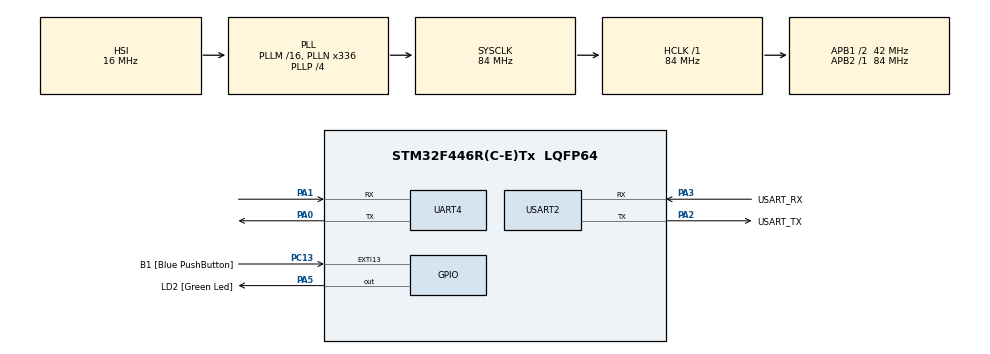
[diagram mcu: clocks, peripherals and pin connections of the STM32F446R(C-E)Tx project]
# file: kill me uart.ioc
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Mcu.Family=STM32F4
Mcu.Name=STM32F446R(C-E)Tx
Mcu.Package=LQFP64
NVIC.PriorityGroup=NVIC_PRIORITYGROUP_0
PA0-WKUP.Mode=Asynchronous
PA0-WKUP.Signal=UART4_TX
PA1.Mode=Asynchronous
PA1.Signal=UART4_RX
PA13.GPIO_Label=TMS
PA13.Mode=Serial_Wire
PA13.Signal=SYS_JTMS-SWDIO
PA14.GPIO_Label=TCK
PA14.Mode=Serial_Wire
PA14.Signal=SYS_JTCK-SWCLK
PA2.GPIO_Label=USART_TX
PA2.Mode=Asynchronous
PA2.Signal=USART2_TX
PA3.GPIO_Label=USART_RX
PA3.Mode=Asynchronous
PA3.Signal=USART2_RX
PA5.GPIO_Label=LD2 [Green Led]
PA5.Signal=GPIO_Output
PB3.GPIO_Label=SWO
PB3.Signal=SYS_JTDO-SWO
PC13.GPIO_Label=B1 [Blue PushButton]
PC13.GPIO_ModeDefaultEXTI=GPIO_MODE_IT_FALLING
PC13.Signal=GPXTI13
PC14-OSC32_IN.Mode=LSE-External-Oscillator
PC14-OSC32_IN.Signal=RCC_OSC32_IN
PC15-OSC32_OUT.Mode=LSE-External-Oscillator
PC15-OSC32_OUT.Signal=RCC_OSC32_OUT
PH0-OSC_IN.Mode=HSE-External-Oscillator
PH0-OSC_IN.Signal=RCC_OSC_IN
PH1-OSC_OUT.Mode=HSE-External-Oscillator
PH1-OSC_OUT.Signal=RCC_OSC_OUT
ProjectManager.HeapSize=0x200
ProjectManager.StackSize=0x400
ProjectManager.TargetToolchain=STM32CubeIDE
RCC.48MHZClocksFreq_Value=84000000
RCC.AHBFreq_Value=84000000
RCC.APB1CLKDivider=RCC_HCLK_DIV2
RCC.APB1Freq_Value=42000000
RCC.APB1TimFreq_Value=84000000
RCC.APB2Freq_Value=84000000
RCC.APB2TimFreq_Value=84000000
RCC.CortexFreq_Value=84000000
RCC.FLatency-AdvancedSettings=FLASH_LATENCY_2
RCC.HCLKFreq_Value=84000000
RCC.HSE_VALUE=8000000
RCC.HSI_VALUE=16000000
RCC.PLLN=336
RCC.PLLP=RCC_PLLP_DIV4
RCC.SYSCLKFreq_VALUE=84000000
RCC.SYSCLKSource=RCC_SYSCLKSOURCE_PLLCLK
RCC.USBFreq_Value=168000000
RCC.VCOOutputFreq_Value=336000000
UART4.VirtualMode=Asynchronous
USART2.VirtualMode=VM_ASYNC
board=NUCLEO-F446RE

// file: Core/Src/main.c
/* USER CODE BEGIN Header */
/**
  ******************************************************************************
  * @file           : main.c
  * @brief          : Main program body
  ******************************************************************************
  * @attention
  *
  * Copyright (c) 2025 STMicroelectronics.
  * All rights reserved.
  *
  * This software is licensed under terms that can be found in the LICENSE file
  * in the root directory of this software component.
  * If no LICENSE file comes with this software, it is provided AS-IS.
  *
  ******************************************************************************
  */
/* USER CODE END Header */
#include "main.h"

/* USER CODE BEGIN Includes */
#include<stdio.h>
#include<inttypes.h>

#include <stdbool.h>
/* USER CODE END Includes */

/* USER CODE BEGIN PTD */
uint8_t rxbuff[16];

int slow=75;

int fast=400;

int Buff1=60;

int Buff2=-60;

int BuffP=80;

int BuffN=-80;

int32_t lx, ly, rx, ry, cro, squ, tri, cir, up, down, left, right, ll1, rr1, ll2, rr2;
/* USER CODE END PTD */

UART_HandleTypeDef huart4;
UART_HandleTypeDef huart2;

void SystemClock_Config(void);
static void MX_GPIO_Init(void);
static void MX_USART2_UART_Init(void);
static void MX_UART4_Init(void);

int main(void)
{

  /* MCU Configuration--------------------------------------------------------*/

  /* Reset of all peripherals, Initializes the Flash interface and the Systick. */
  HAL_Init();

  /* Configure the system clock */
  SystemClock_Config();

  /* Initialize all configured peripherals */
  MX_GPIO_Init();
  MX_USART2_UART_Init();
  MX_UART4_Init();
  HAL_UART_Receive(&huart4, rxbuff, 64,1000);
  /* Infinite loop */
  while (1)
  {
	  HAL_StatusTypeDef status;

	  	  	 	 	   status=HAL_UART_Receive(&huart4, rxbuff,64,1000);

	  	  	 	 	   if (status == HAL_OK)

	  	  	 	 	   {

	  	  	 	 	   // Convert the received bytes to signed integers

	  	  	 	 	   lx = (rxbuff[1] & 0x80) ? (int32_t)rxbuff[1] - 256 : (int32_t)rxbuff[1];

	  	  	 	 	   ly = (rxbuff[2] & 0x80) ? (int32_t)rxbuff[2] - 256 : (int32_t)rxbuff[2];

	  	  	 	 	   rx = (rxbuff[3] & 0x80) ? (int32_t)rxbuff[3] - 256 : (int32_t)rxbuff[3];

	  	  	 	 	   ry = (rxbuff[4] & 0x80) ? (int32_t)rxbuff[4] - 256 : (int32_t)rxbuff[4];

	  	  	 	 	   cro= (rxbuff[5] & 0x80) ? (int32_t)rxbuff[5] - 256 : (int32_t)rxbuff[5];

	  	  	 	 	   squ= (rxbuff[6] & 0x80) ? (int32_t)rxbuff[6] - 256 : (int32_t)rxbuff[6];

	  	  	 	 	   tri= (rxbuff[7] & 0x80) ? (int32_t)rxbuff[7] - 256 : (int32_t)rxbuff[7];

	  	  	 	 	   cir= (rxbuff[8] & 0x80) ? (int32_t)rxbuff[8] - 256 : (int32_t)rxbuff[8];

	  	  	 	 	   up= (rxbuff[9] & 0x80) ? (int32_t)rxbuff[9] - 256 : (int32_t)rxbuff[9];

	  	  	 	 	   down= (rxbuff[10] & 0x80) ? (int32_t)rxbuff[10] - 256 : (int32_t)rxbuff[10];

	  	  	 	 	   left= (rxbuff[11] & 0x80) ? (int32_t)rxbuff[11] - 256 : (int32_t)rxbuff[11];

	  	  	 	 	   right=(rxbuff[12] & 0x80) ? (int32_t)rxbuff[12] - 256 : (int32_t)rxbuff[12];

	  	  	 	 	   ll1= (rxbuff[13] & 0x80) ? (int32_t)rxbuff[13] - 256 : (int32_t)rxbuff[13];

	  	  	 	 	   ll2= (rxbuff[14] & 0x80) ? (int32_t)rxbuff[14] - 256 : (int32_t)rxbuff[14];

	  	  	 	 	   rr1= (rxbuff[15] & 0x80) ? (int32_t)rxbuff[15] - 256 : (int32_t)rxbuff[15];

	  	  	 	 	   rr2= (rxbuff[16] & 0x80) ? (int32_t)rxbuff[16] - 256 : (int32_t)rxbuff[16];

	  	  	 	 	   // Print the received values

	  	  	 	 	   printf("Received Integers:\n");

	  	  	 	 	   printf("lx: %ld\n", lx);

	  	  	 	 	   printf("ly: %ld\n", ly);

	  	  	 	 	   printf("rx: %ld\n", rx);

	  	  	 	 	   printf("ry: %ld\n", ry);

	  	  	 	 	   printf("cro: %ld\n", cro);

	  	  	 	 	   printf("squ: %ld\n", squ);

	  	  	 	 	   printf("tri: %ld\n", tri);

	  	  	 	 	   printf("cir: %ld\n", cir);

	  	  	 	 	   printf("up: %ld\n", up);

	  	  	 	 	   printf("down: %ld\n", down);

	  	  	 	 	   printf("left: %ld\n", left);

	  	  	 	 	   printf("right: %ld\n", right);

	  	  	 	 	   printf("ll1: %ld\n", ll1);

	  	  	 	 	   printf("ll2: %ld\n", ll2);

	  	  	 	 	   printf("rr1: %ld\n", rr1);

	  	  	 	 	   printf("rr2: %ld\n", rr2);

	  	  	 	 	   }

	  	  	 	 	   else{

	  	  	 	 	   ry = 0;

	  	  	 	 	   rx = 0;

	  	  	 	 	   lx = 0;

	  	  	 	 	   ly = 0;

	  	  	 	 	   cro = 0;

	  	  	 	 	   squ = 0;

	  	  	 	 	   tri = 0;

	  	  	 	 	   cir = 0;

	  	  	 	 	   up = 0;

	  	  	 	 	   down = 0;

	  	  	 	 	   left = 0;

	  	  	 	 	   right = 0;

	  	  	 	 	   ll1=0;

	  	  	 	 	   ll2=0;

	  	  	 	 	   rr1=0;

	  	  	 	 	   rr2=0;

	  	 	 	   }
  }
}

void SystemClock_Config(void)
{
  RCC_OscInitTypeDef RCC_OscInitStruct = {0};
  RCC_ClkInitTypeDef RCC_ClkInitStruct = {0};

  /** Configure the main internal regulator output voltage
  */
  __HAL_RCC_PWR_CLK_ENABLE();
  __HAL_PWR_VOLTAGESCALING_CONFIG(PWR_REGULATOR_VOLTAGE_SCALE3);

  /** Initializes the RCC Oscillators according to the specified parameters
  * in the RCC_OscInitTypeDef structure.
  */
  RCC_OscInitStruct.OscillatorType = RCC_OSCILLATORTYPE_HSI;
  RCC_OscInitStruct.HSIState = RCC_HSI_ON;
  RCC_OscInitStruct.HSICalibrationValue = RCC_HSICALIBRATION_DEFAULT;
  RCC_OscInitStruct.PLL.PLLState = RCC_PLL_ON;
  RCC_OscInitStruct.PLL.PLLSource = RCC_PLLSOURCE_HSI;
  RCC_OscInitStruct.PLL.PLLM = 16;
  RCC_OscInitStruct.PLL.PLLN = 336;
  RCC_OscInitStruct.PLL.PLLP = RCC_PLLP_DIV4;
  RCC_OscInitStruct.PLL.PLLQ = 2;
  RCC_OscInitStruct.PLL.PLLR = 2;
  if (HAL_RCC_OscConfig(&RCC_OscInitStruct) != HAL_OK)
  {
    Error_Handler();
  }

  /** Initializes the CPU, AHB and APB buses clocks
  */
  RCC_ClkInitStruct.ClockType = RCC_CLOCKTYPE_HCLK|RCC_CLOCKTYPE_SYSCLK
                              |RCC_CLOCKTYPE_PCLK1|RCC_CLOCKTYPE_PCLK2;
  RCC_ClkInitStruct.SYSCLKSource = RCC_SYSCLKSOURCE_PLLCLK;
  RCC_ClkInitStruct.AHBCLKDivider = RCC_SYSCLK_DIV1;
  RCC_ClkInitStruct.APB1CLKDivider = RCC_HCLK_DIV2;
  RCC_ClkInitStruct.APB2CLKDivider = RCC_HCLK_DIV1;

  if (HAL_RCC_ClockConfig(&RCC_ClkInitStruct, FLASH_LATENCY_2) != HAL_OK)
  {
    Error_Handler();
  }
}

static void MX_UART4_Init(void)
{

  huart4.Instance = UART4;
  huart4.Init.BaudRate = 115200;
  huart4.Init.WordLength = UART_WORDLENGTH_8B;
  huart4.Init.StopBits = UART_STOPBITS_1;
  huart4.Init.Parity = UART_PARITY_NONE;
  huart4.Init.Mode = UART_MODE_TX_RX;
  huart4.Init.HwFlowCtl = UART_HWCONTROL_NONE;
  huart4.Init.OverSampling = UART_OVERSAMPLING_16;
  if (HAL_UART_Init(&huart4) != HAL_OK)
  {
    Error_Handler();
  }

}

static void MX_USART2_UART_Init(void)
{

  huart2.Instance = USART2;
  huart2.Init.BaudRate = 115200;
  huart2.Init.WordLength = UART_WORDLENGTH_8B;
  huart2.Init.StopBits = UART_STOPBITS_1;
  huart2.Init.Parity = UART_PARITY_NONE;
  huart2.Init.Mode = UART_MODE_TX_RX;
  huart2.Init.HwFlowCtl = UART_HWCONTROL_NONE;
  huart2.Init.OverSampling = UART_OVERSAMPLING_16;
  if (HAL_UART_Init(&huart2) != HAL_OK)
  {
    Error_Handler();
  }

}

static void MX_GPIO_Init(void)
{
  GPIO_InitTypeDef GPIO_InitStruct = {0};

  /* GPIO Ports Clock Enable */
  __HAL_RCC_GPIOC_CLK_ENABLE();
  __HAL_RCC_GPIOH_CLK_ENABLE();
  __HAL_RCC_GPIOA_CLK_ENABLE();
  __HAL_RCC_GPIOB_CLK_ENABLE();

  /*Configure GPIO pin Output Level */
  HAL_GPIO_WritePin(LD2_GPIO_Port, LD2_Pin, GPIO_PIN_RESET);

  /*Configure GPIO pin : B1_Pin */
  GPIO_InitStruct.Pin = B1_Pin;
  GPIO_InitStruct.Mode = GPIO_MODE_IT_FALLING;
  GPIO_InitStruct.Pull = GPIO_NOPULL;
  HAL_GPIO_Init(B1_GPIO_Port, &GPIO_InitStruct);

  /*Configure GPIO pin : LD2_Pin */
  GPIO_InitStruct.Pin = LD2_Pin;
  GPIO_InitStruct.Mode = GPIO_MODE_OUTPUT_PP;
  GPIO_InitStruct.Pull = GPIO_NOPULL;
  GPIO_InitStruct.Speed = GPIO_SPEED_FREQ_LOW;
  HAL_GPIO_Init(LD2_GPIO_Port, &GPIO_InitStruct);

}

void Error_Handler(void)
{
  __disable_irq();
  while (1)
  {
  }
}
